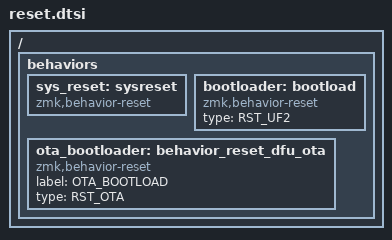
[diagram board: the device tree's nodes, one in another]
/*
 * Copyright (c) 2020 The ZMK Contributors
 *
 * SPDX-License-Identifier: MIT
 */

#include <dt-bindings/zmk/reset.h>

/ {
    behaviors {
        // Behavior can be invoked on peripherals, so name must be <= 8 characters.
        sys_reset: sysreset {
            compatible = "zmk,behavior-reset";
            #binding-cells = <0>;
        };

        // Behavior can be invoked on peripherals, so name must be <= 8 characters.
        bootloader: bootload {
            compatible = "zmk,behavior-reset";
            type = <RST_UF2>;
            #binding-cells = <0>;
        };

        ota_bootloader: behavior_reset_dfu_ota {
            compatible = "zmk,behavior-reset";
            label = "OTA_BOOTLOAD";
            type = <RST_OTA>;
            #binding-cells = <0>;
        };
    };
};
